VERSION ""

NS_ :

BS_:

BU_: XXX

BO_ 85 CID_SJHKTK: 8 XXX
 SG_ sig_qkastz : 40|1@1+ (1,0) [0|1] "" XXX
 SG_ sig_yzoryc : 56|8@1+ (1,0) [0|255] "" XXX

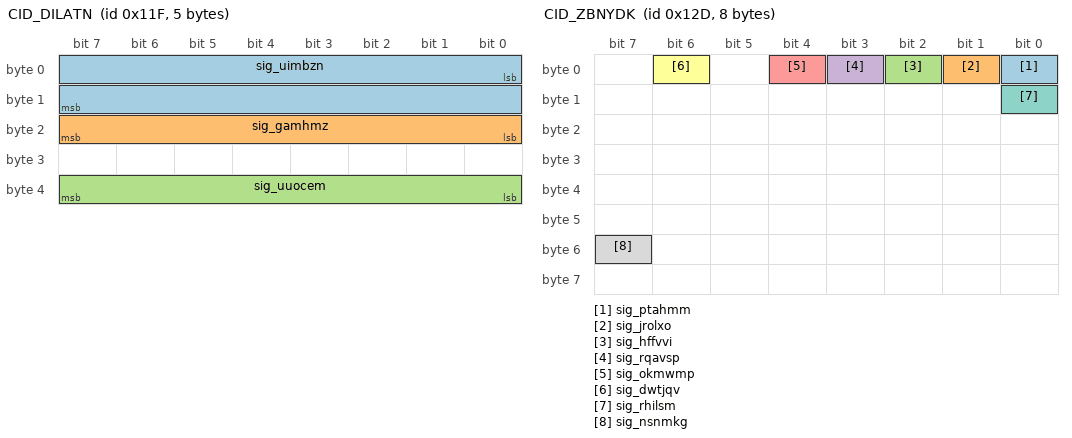
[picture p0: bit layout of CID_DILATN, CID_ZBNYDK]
BO_ 287 CID_DILATN: 5 XXX
 SG_ sig_uimbzn : 0|16@1- (0.1,0) [-450|450] "" XXX
 SG_ sig_gamhmz : 16|8@1+ (4,0) [0|1020] "" XXX
 SG_ sig_uuocem : 32|8@1+ (1,0) [0|255] "" XXX

BO_ 289 CID_TLPPWU: 8 XXX
 SG_ sig_iyrkwj : 0|12@1+ (1,0) [0|255] "" XXX

BO_ 301 CID_ZBNYDK: 8 XXX
 SG_ sig_ptahmm : 0|1@0+ (1,0) [0|1] "" XXX
 SG_ sig_jrolxo : 1|1@0+ (1,0) [0|1] "" XXX
 SG_ sig_hffvvi : 2|1@0+ (1,0) [0|1] "" XXX
 SG_ sig_rqavsp : 3|1@0+ (1,0) [0|1] "" XXX
 SG_ sig_okmwmp : 4|1@0+ (1,0) [0|1] "" XXX
 SG_ sig_dwtjqv : 6|1@0+ (1,0) [0|1] "" XXX
 SG_ sig_rhilsm : 8|1@0+ (1,0) [0|1] "" XXX
 SG_ sig_nsnmkg : 55|1@0+ (1,0) [0|1] "" XXX

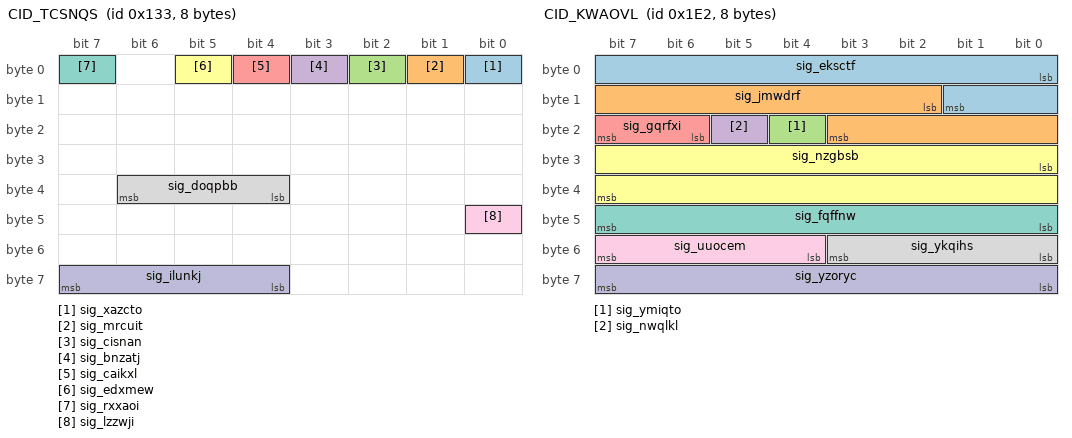
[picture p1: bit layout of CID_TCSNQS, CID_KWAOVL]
BO_ 307 CID_TCSNQS: 8 XXX
 SG_ sig_xazcto : 0|1@0+ (1,0) [0|1] "" XXX
 SG_ sig_mrcuit : 1|1@1+ (1,0) [0|1] "" XXX
 SG_ sig_cisnan : 2|1@1+ (1,0) [0|1] "" XXX
 SG_ sig_bnzatj : 3|1@1+ (1,0) [0|1] "" XXX
 SG_ sig_caikxl : 4|1@0+ (1,0) [0|1] "" XXX
 SG_ sig_edxmew : 5|1@0+ (1,0) [0|1] "" XXX
 SG_ sig_rxxaoi : 7|1@0+ (1,0) [0|1] "" XXX
 SG_ sig_doqpbb : 36|3@1+ (1,0) [0|7] "" XXX
 SG_ sig_lzzwji : 40|1@0+ (1,0) [0|1] "" XXX
 SG_ sig_ilunkj : 63|4@0+ (1,0) [0|15] "" XXX

BO_ 482 CID_KWAOVL: 8 XXX
 SG_ sig_eksctf : 0|10@1- (0.01,0) [0|5] "" XXX
 SG_ sig_jmwdrf : 10|10@1- (0.01,0) [-5|0] "" XXX
 SG_ sig_ymiqto : 20|1@0+ (1,0) [0|1] "" XXX
 SG_ sig_nwqlkl : 21|1@0+ (1,0) [0|1] "" XXX
 SG_ sig_gqrfxi : 22|2@1+ (1,0) [0|1] "" XXX
 SG_ sig_nzgbsb : 24|16@1- (0.1,0) [-780|779.9] "" XXX
 SG_ sig_fqffnw : 47|8@0+ (1,0) [0|255] "" XXX
 SG_ sig_ykqihs : 48|4@1+ (1,0) [0|15] "" XXX
 SG_ sig_uuocem : 52|4@1+ (1,0) [0|15] "" XXX
 SG_ sig_yzoryc : 56|8@1+ (1,0) [0|255] "" XXX

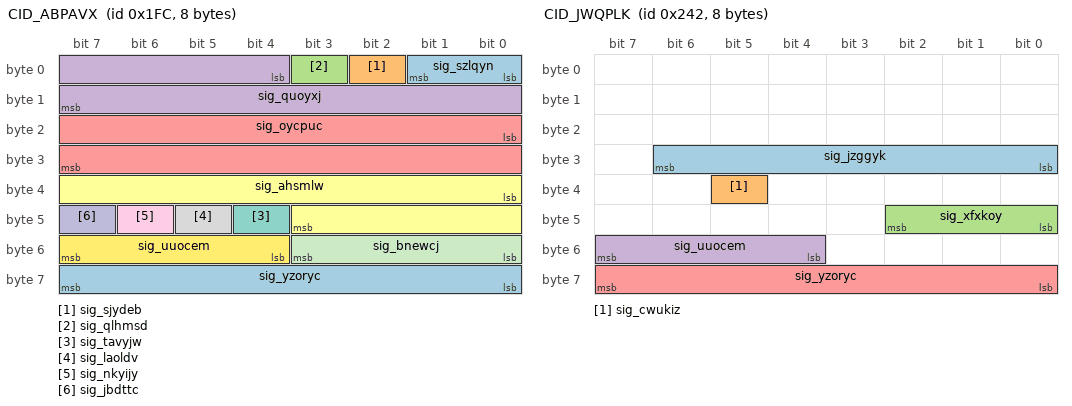
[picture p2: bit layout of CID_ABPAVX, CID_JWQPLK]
BO_ 508 CID_ABPAVX: 8 XXX
 SG_ sig_szlqyn : 0|2@1+ (1,0) [0|1] "" XXX
 SG_ sig_sjydeb : 2|1@1+ (1,0) [0|1] "" XXX
 SG_ sig_qlhmsd : 3|1@0+ (1,0) [0|1] "" XXX
 SG_ sig_quoyxj : 4|12@1- (1,0) [-2048|2047] "" XXX
 SG_ sig_oycpuc : 16|16@1- (0.1,0) [-780|779.9] "Deg" XXX
 SG_ sig_ahsmlw : 32|12@1- (0.01,0) [0|63] "" XXX
 SG_ sig_tavyjw : 44|1@0+ (1,0) [0|1] "" XXX
 SG_ sig_laoldv : 45|1@1+ (1,0) [0|255] "" XXX
 SG_ sig_nkyijy : 46|1@1+ (1,0) [0|1] "" XXX
 SG_ sig_jbdttc : 47|1@0+ (1,0) [0|3] "" XXX
 SG_ sig_bnewcj : 48|4@1+ (1,0) [0|15] "" XXX
 SG_ sig_uuocem : 52|4@1+ (1,0) [0|15] "" XXX
 SG_ sig_yzoryc : 56|8@1+ (1,0) [0|255] "" XXX

BO_ 578 CID_JWQPLK: 8 XXX
 SG_ sig_jzggyk : 30|7@0+ (1,0) [0|127] "" XXX
 SG_ sig_cwukiz : 37|1@0+ (1,0) [0|1] "" XXX
 SG_ sig_xfxkoy : 40|3@1+ (1,0) [0|7] "" XXX
 SG_ sig_uuocem : 55|4@0+ (1,0) [0|15] "" XXX
 SG_ sig_yzoryc : 56|8@1+ (1,0) [0|255] "" XXX

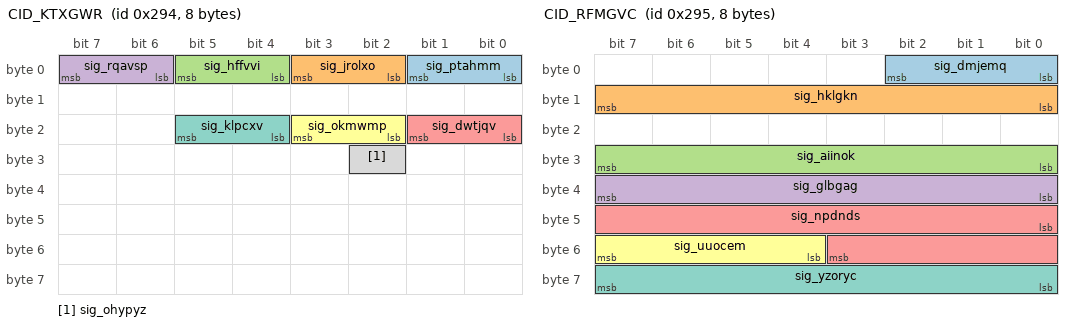
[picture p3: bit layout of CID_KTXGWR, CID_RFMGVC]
BO_ 660 CID_KTXGWR: 8 XXX
 SG_ sig_ptahmm : 1|2@0+ (1,0) [0|3] "" XXX
 SG_ sig_jrolxo : 3|2@0+ (1,0) [0|3] "" XXX
 SG_ sig_hffvvi : 5|2@0+ (1,0) [0|3] "" XXX
 SG_ sig_rqavsp : 7|2@0+ (1,0) [0|3] "" XXX
 SG_ sig_dwtjqv : 17|2@0+ (1,0) [0|3] "" XXX
 SG_ sig_okmwmp : 19|2@0+ (1,0) [0|3] "" XXX
 SG_ sig_klpcxv : 21|2@0+ (1,0) [0|3] "" XXX
 SG_ sig_ohypyz : 26|1@0+ (1,0) [0|1] "" XXX

BO_ 661 CID_RFMGVC: 8 XXX
 SG_ sig_dmjemq : 2|3@0+ (1,0) [0|7] "" XXX
 SG_ sig_hklgkn : 15|8@0+ (1,0) [0|255] "" XXX
 SG_ sig_aiinok : 31|8@0+ (1,0) [0|255] "" XXX
 SG_ sig_glbgag : 32|8@1+ (1,0) [0|255] "" XXX
 SG_ sig_npdnds : 40|12@1+ (1,0) [0|255] "" XXX
 SG_ sig_uuocem : 52|4@1+ (1,0) [0|15] "" XXX
 SG_ sig_yzoryc : 63|8@0+ (1,0) [0|255] "" XXX

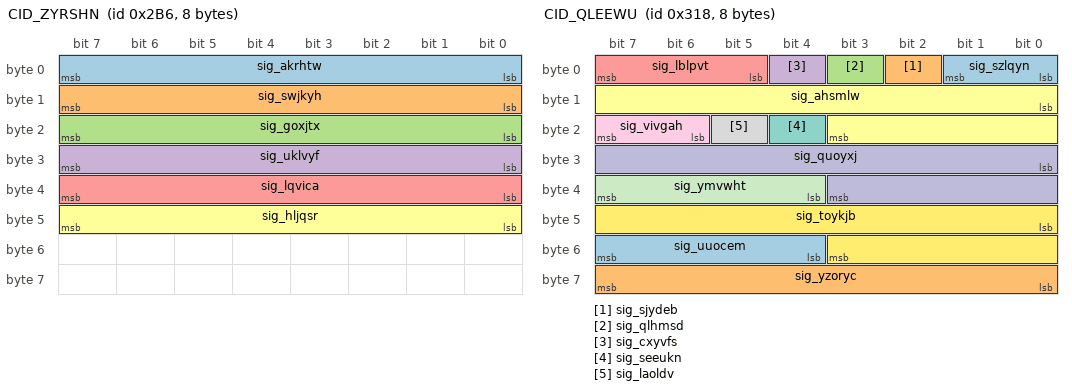
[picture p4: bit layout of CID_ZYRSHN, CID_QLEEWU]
BO_ 694 CID_ZYRSHN: 8 XXX
 SG_ sig_akrhtw : 7|8@0+ (1,0) [0|255] "" XXX
 SG_ sig_swjkyh : 15|8@0+ (1,0) [0|255] "" XXX
 SG_ sig_goxjtx : 23|8@0+ (1,0) [0|255] "" XXX
 SG_ sig_uklvyf : 31|8@0+ (1,0) [0|255] "" XXX
 SG_ sig_lqvica : 39|8@0+ (1,0) [0|255] "" XXX
 SG_ sig_hljqsr : 47|8@0+ (1,0) [0|255] "" XXX

BO_ 790 CID_MGPEZT: 8 XXX
 SG_ sig_imxmzn : 3|4@0+ (1,0) [0|1] "" XXX
 SG_ sig_qgqulv : 4|2@1+ (1,0) [0|3] "" XXX
 SG_ sig_kglcib : 6|2@1+ (1,0) [0|3] "" XXX
 SG_ sig_uzgetg : 8|2@1+ (1,0) [0|3] "" XXX
 SG_ sig_amasha : 10|1@1+ (1,0) [0|1] "" XXX
 SG_ sig_xtzqds : 11|4@1+ (1,0) [0|1] "" XXX
 SG_ sig_qhalec : 15|1@0+ (1,0) [0|1] "" XXX
 SG_ sig_nzgbsb : 16|11@1- (1,0) [-1024|1023] "" XXX
 SG_ sig_ymiqto : 27|1@1+ (1,0) [0|1] "" XXX
 SG_ sig_nwqlkl : 28|1@1+ (1,0) [0|3] "" XXX
 SG_ sig_kojdcz : 29|1@0+ (1,0) [0|1] "" XXX
 SG_ sig_uotbcf : 30|1@0+ (1,0) [0|1] "" XXX
 SG_ sig_tjhsio : 31|1@0+ (1,0) [0|1] "" XXX
 SG_ sig_qbhrbz : 32|2@1+ (1,0) [0|3] "" XXX
 SG_ sig_oauflc : 34|2@1+ (1,0) [0|3] "" XXX
 SG_ sig_gfvkgr : 36|4@1+ (1,0) [0|3] "" XXX
 SG_ sig_rgzfan : 40|8@1+ (5,-5) [-5|1270] "" XXX
 SG_ sig_gqqbqm : 49|2@0+ (1,0) [0|3] "" XXX
 SG_ sig_vinhvk : 51|2@0+ (1,0) [0|3] "" XXX
 SG_ sig_uuocem : 52|4@1+ (1,0) [0|15] "" XXX
 SG_ sig_yzoryc : 56|8@1+ (1,0) [0|15] "" XXX

BO_ 792 CID_QLEEWU: 8 XXX
 SG_ sig_szlqyn : 0|2@1+ (1,0) [0|1] "" XXX
 SG_ sig_sjydeb : 2|1@1+ (1,0) [0|1] "" XXX
 SG_ sig_qlhmsd : 3|1@1+ (1,0) [0|1] "" XXX
 SG_ sig_cxyvfs : 4|1@1+ (1,0) [0|1] "" XXX
 SG_ sig_lblpvt : 5|3@1+ (1,0) [0|1] "" XXX
 SG_ sig_ahsmlw : 8|12@1- (1,0) [-2048|2047] "" XXX
 SG_ sig_seeukn : 20|1@1+ (1,0) [0|1] "" XXX
 SG_ sig_laoldv : 21|1@1+ (1,0) [0|1] "" XXX
 SG_ sig_vivgah : 22|2@1+ (1,0) [0|15] "" XXX
 SG_ sig_quoyxj : 24|12@1- (1,0) [-2048|2047] "" XXX
 SG_ sig_ymvwht : 36|4@1+ (1,0) [0|15] "" XXX
 SG_ sig_toykjb : 40|12@1+ (1,0) [0|4095] "" XXX
 SG_ sig_uuocem : 52|4@1+ (1,0) [0|15] "" XXX
 SG_ sig_yzoryc : 56|8@1+ (1,0) [0|255] "" XXX

BO_ 813 CID_XWEZPY: 8 XXX
 SG_ sig_hheysp : 0|9@1+ (0.5,0) [0|255.5] "" XXX
 SG_ sig_thycyz : 9|1@1+ (1,0) [0|1] "" XXX
 SG_ sig_ixvhtk : 10|3@1+ (1,0) [0|7] "" XXX
 SG_ sig_vwxhhb : 13|3@1+ (1,0) [0|7] "" XXX
 SG_ sig_btqjhs : 16|1@1+ (1,0) [0|1] "" XXX
 SG_ sig_scsyqh : 17|1@1+ (1,0) [0|1] "" XXX
 SG_ sig_qlhmsd : 18|1@1+ (1,0) [0|1] "" XXX
 SG_ sig_elxvyc : 19|3@1+ (1,0) [0|1] "" XXX
 SG_ sig_gbrfaw : 22|1@0+ (1,0) [0|1] "" XXX
 SG_ sig_vtcmdw : 23|1@0+ (1,0) [0|1] "" XXX
 SG_ sig_uzgetg : 24|1@1+ (1,0) [0|1] "" XXX
 SG_ sig_gtmbdz : 25|7@1+ (1,0) [0|127] "" XXX
 SG_ sig_vhoztr : 32|4@1+ (1,0) [0|15] "" XXX
 SG_ sig_rrioof : 36|12@1+ (1,0) [0|4095] "" XXX
 SG_ sig_uuocem : 48|4@1+ (1,0) [0|15] "" XXX
 SG_ sig_ydzvpg : 55|4@0+ (1,0) [0|15] "" XXX
 SG_ sig_yzoryc : 56|8@1+ (1,0) [0|255] "" XXX

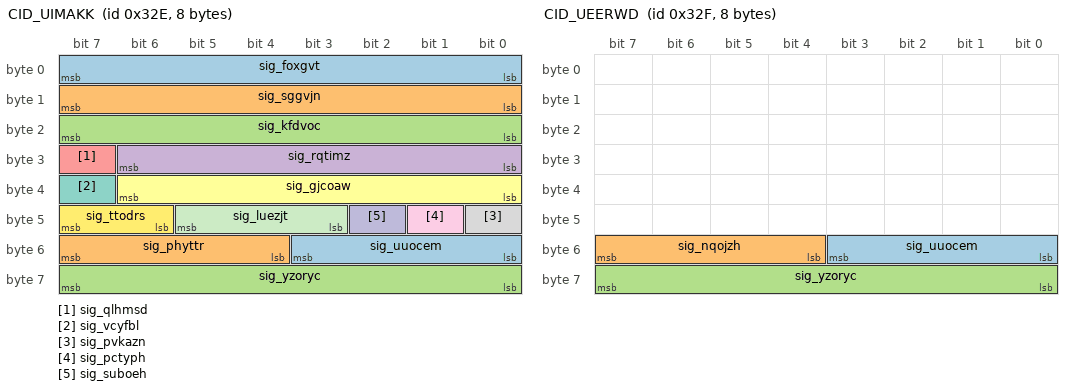
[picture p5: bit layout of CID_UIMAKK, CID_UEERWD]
BO_ 814 CID_UIMAKK: 8 XXX
 SG_ sig_foxgvt : 0|8@1+ (0.05,-5) [-100|155] "" XXX
 SG_ sig_sggvjn : 8|8@1+ (0.05,-5) [0|1.26] "" XXX
 SG_ sig_kfdvoc : 16|8@1+ (0.05,-5) [0|1.26] "" XXX
 SG_ sig_rqtimz : 24|7@1+ (0.2,0) [0|12.7] "" XXX
 SG_ sig_qlhmsd : 31|1@0+ (1,0) [0|1] "" XXX
 SG_ sig_gjcoaw : 32|7@1+ (0.2,-16) [0|12.7] "" XXX
 SG_ sig_vcyfbl : 39|1@0+ (1,0) [0|1] "" XXX
 SG_ sig_pvkazn : 40|1@0+ (1,0) [0|1] "" XXX
 SG_ sig_pctyph : 41|1@0+ (1,0) [0|1] "" XXX
 SG_ sig_suboeh : 42|1@1+ (1,0) [0|3] "" XXX
 SG_ sig_luezjt : 45|3@0+ (1,0) [0|1] "" XXX
 SG_ sig_ttodrs : 46|2@1+ (1,0) [0|3] "" XXX
 SG_ sig_uuocem : 48|4@1+ (1,0) [0|15] "" XXX
 SG_ sig_phyttr : 55|4@0+ (1,0) [0|15] "" XXX
 SG_ sig_yzoryc : 56|8@1+ (1,0) [0|255] "" XXX

BO_ 815 CID_UEERWD: 8 XXX
 SG_ sig_uuocem : 48|4@1+ (1,0) [0|15] "" XXX
 SG_ sig_nqojzh : 55|4@0+ (1,0) [0|15] "" XXX
 SG_ sig_yzoryc : 56|8@1+ (1,0) [0|255] "" XXX

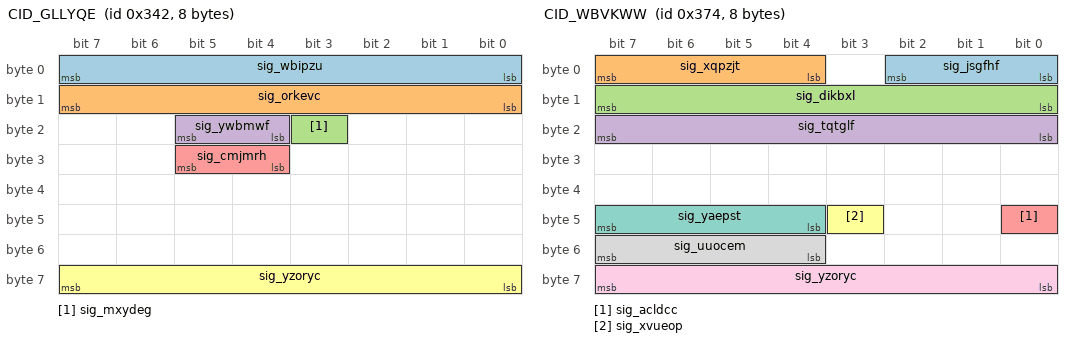
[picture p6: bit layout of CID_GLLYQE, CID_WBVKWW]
BO_ 834 CID_GLLYQE: 8 XXX
 SG_ sig_wbipzu : 0|8@1+ (0.01,0) [0|2.55] "" XXX
 SG_ sig_orkevc : 8|8@1+ (0.01,0) [0|2.55] "" XXX
 SG_ sig_mxydeg : 19|1@1+ (1,0) [0|1] "" XXX
 SG_ sig_ywbmwf : 20|2@1+ (1,0) [0|255] "" XXX
 SG_ sig_cmjmrh : 28|2@1+ (1,0) [0|1] "" XXX
 SG_ sig_yzoryc : 56|8@1+ (1,0) [0|255] "" XXX

 BO_ 884 CID_WBVKWW: 8 MRR
 SG_ sig_jsgfhf : 2|3@0+ (1,0) [0|3] "" MRR
 SG_ sig_xqpzjt : 7|4@0+ (1,0) [0|15] "" MRR
 SG_ sig_dikbxl : 15|8@0+ (0.1,-12) [0|255] "" MRR
 SG_ sig_tqtglf : 23|8@0+ (1,-100) [0|255] "" MRR
 SG_ sig_acldcc : 40|1@0+ (1,0) [0|3] "" MRR
 SG_ sig_xvueop : 43|1@0+ (1,0) [0|1] "" XXX
 SG_ sig_yaepst : 44|4@1+ (1,0) [0|15] "" XXX
 SG_ sig_uuocem : 52|4@1+ (1,0) [0|15] "" MRR
 SG_ sig_yzoryc : 56|8@1+ (1,0) [0|255] "" MRR

BO_ 944 CID_QFRRRI: 8 XXX
 SG_ sig_nxnrxz : 1|2@0+ (1,0) [0|3] "" XXX
 SG_ sig_qncqly : 2|1@0+ (1,0) [0|1] "" XXX
 SG_ sig_lndgqs : 4|2@0+ (1,0) [0|3] "" XXX
 SG_ sig_ejscnz : 5|1@0+ (1,0) [0|1] "" XXX
 SG_ sig_mysczk : 6|1@0+ (1,0) [0|1] "" XXX
 SG_ sig_pdrhgg : 7|1@0+ (1,0) [0|1] "" XXX
 SG_ sig_koqviv : 8|1@0+ (1,0) [0|1] "" XXX
 SG_ sig_nimckg : 11|3@0+ (1,0) [0|7] "" XXX
 SG_ sig_zdizhi : 12|1@0+ (1,0) [0|1] "" XXX
 SG_ sig_bbyfsd : 14|2@0+ (1,0) [0|3] "" XXX
 SG_ sig_cmgrqh : 15|1@0+ (1,0) [0|1] "" XXX
 SG_ sig_xmpsuc : 16|1@0+ (1,0) [0|1] "" XXX
 SG_ sig_ctptfi : 18|2@0+ (1,0) [0|3] "" XXX
 SG_ sig_fiaqlt : 19|1@0+ (1,0) [0|1] "" XXX
 SG_ sig_bcvsni : 23|4@0+ (1,0) [0|15] "" XXX
 SG_ sig_eusztu : 24|28@1+ (1,0) [0|268435455] "" XXX
 SG_ sig_uuocem : 52|4@1+ (1,0) [0|15] "" XXX
 SG_ sig_yzoryc : 56|8@1+ (1,0) [0|255] "" XXX

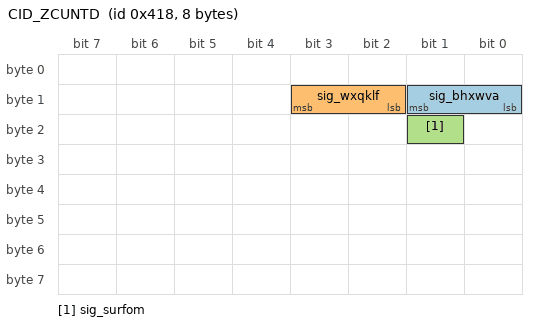
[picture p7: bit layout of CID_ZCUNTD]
BO_ 1048 CID_ZCUNTD: 8 XXX
 SG_ sig_bhxwva : 9|2@0+ (1,0) [0|1] "" XXX
 SG_ sig_wxqklf : 11|2@0+ (1,0) [0|1] "" XXX
 SG_ sig_surfom : 17|1@0+ (1,0) [0|1] "" XXX

VAL_ 578 sig_xfxkoy 4 "D" 2 "R" 3 "N" 1 "P";
VAL_ 790 sig_imxmzn 11 "AutoFullBeamActive" 2 "AutoFullBeamInactive";
VAL_ 790 sig_qgqulv 0 "GRAY" 1 "GREEN" 2 "YELLOW" 3 "RED";
VAL_ 790 sig_kglcib 3 "ALARM_AND_LKA" 2 "LKA" 1 "ALARM" 0 "DISABLE";
VAL_ 790 sig_oauflc 0 "GRAY" 1 "GREEN" 2 "YELLOW" 3 "RED";
VAL_ 790 sig_gqqbqm 0 "VIBRATION" 1 "AUDIO" 2 "AUDIO_AND_VIBRATION";
VAL_ 792 sig_szlqyn 0 "NotReady" 1 "Ready" 2 "Active" 3 "TemporaryFail";
VAL_ 813 sig_ixvhtk 4 "4BAR" 3 "3BAR" 2 "2BAR" 1 "1BAR";
VAL_ 813 sig_elxvyc 0 "OFF" 2 "ACC_ON" 3 "ACC_ACTIVE" 5 "FORCE_ACCEL" 7 "ERROR";
VAL_ 813 sig_gtmbdz 36 "ACC_ERROR" 22 "OVERRIDE" 12 "ENGAGE" 8 "DISENGAGE" 20 "ACC_ON" 32 "ACC_OFF" 48 "CHECK_GEAR_D" 16 "FORCE_ACCEL" 0 "NONE";
VAL_ 814 sig_luezjt 0 "Off" 1 "Passive" 2 "StandBy" 3 "ActiveControl" 4 "BrakeOnly" 5 "Override" 6 "Standstill" 7 "Failure";
VAL_ 814 sig_ttodrs 0 "Softoff" 1 "Fastoff" 2 "Immediateoff" 3 "Initial";
VAL_ 834 sig_ywbmwf 2 "SPORT" 1 "ECO" 0 "SNOW";
VAL_ 834 sig_cmjmrh 3 "HEV" 2 "FORCE_EV" 1 "EV";
VAL_ 944 sig_lndgqs 0 "NOTPRESSED" 1 "DOWN_SETSPEED" 3 "UP_RESETSPEED";
